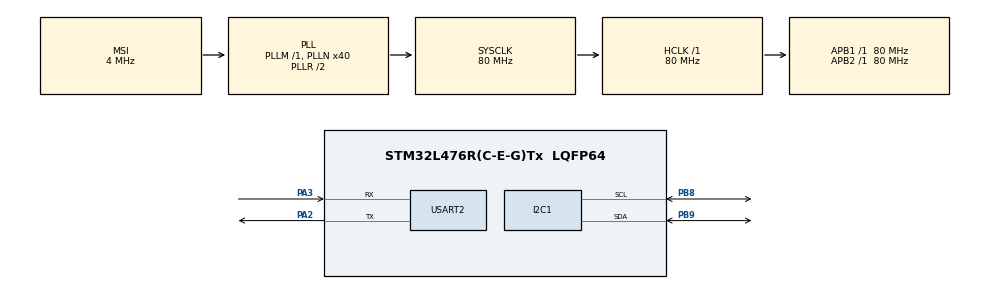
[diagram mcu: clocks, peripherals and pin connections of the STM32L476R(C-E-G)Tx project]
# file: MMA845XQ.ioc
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I2C1.I2C_Fall_Time=20
I2C1.I2C_Rise_Time=20
I2C1.Timing=0x4040415A
Mcu.Family=STM32L4
Mcu.Name=STM32L476R(C-E-G)Tx
Mcu.Package=LQFP64
NVIC.PriorityGroup=NVIC_PRIORITYGROUP_4
PA13\ (JTMS-SWDIO).Mode=Trace_Asynchronous_SW
PA13\ (JTMS-SWDIO).Signal=SYS_JTMS-SWDIO
PA14\ (JTCK-SWCLK).Mode=Trace_Asynchronous_SW
PA14\ (JTCK-SWCLK).Signal=SYS_JTCK-SWCLK
PA2.Mode=Asynchronous
PA2.Signal=USART2_TX
PA3.Mode=Asynchronous
PA3.Signal=USART2_RX
PB3\ (JTDO-TRACESWO).Mode=Trace_Asynchronous_SW
PB3\ (JTDO-TRACESWO).Signal=SYS_JTDO-SWO
PB8.Mode=I2C
PB8.Signal=I2C1_SCL
PB9.Mode=I2C
PB9.Signal=I2C1_SDA
PC14-OSC32_IN\ (PC14).Mode=LSE-External-Oscillator
PC14-OSC32_IN\ (PC14).Signal=RCC_OSC32_IN
PC15-OSC32_OUT\ (PC15).Mode=LSE-External-Oscillator
PC15-OSC32_OUT\ (PC15).Signal=RCC_OSC32_OUT
ProjectManager.HeapSize=0x200
ProjectManager.StackSize=0x400
ProjectManager.TargetToolchain=SW4STM32
RCC.AHBFreq_Value=80000000
RCC.APB1Freq_Value=80000000
RCC.APB1TimFreq_Value=80000000
RCC.APB2Freq_Value=80000000
RCC.APB2TimFreq_Value=80000000
RCC.CortexFreq_Value=80000000
RCC.HCLKFreq_Value=80000000
RCC.HSE_VALUE=8000000
RCC.HSI_VALUE=16000000
RCC.MSI_VALUE=4000000
RCC.PLLN=40
RCC.SYSCLKFreq_VALUE=80000000
RCC.SYSCLKSource=RCC_SYSCLKSOURCE_PLLCLK
RCC.VCOOutputFreq_Value=160000000
USART2.VirtualMode-Asynchronous=VM_ASYNC
VP_WWDG_VS_WWDG.Mode=WWDG_Activate
board=MMA845XQ

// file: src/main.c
/**
 ******************************************************************************
 * File Name          : main.c
 * Description        : Main program body
 ******************************************************************************
 ** This notice applies to any and all portions of this file
 * that are not between comment pairs USER CODE BEGIN and
 * USER CODE END. Other portions of this file, whether
 * inserted by the user or by software development tools
 * are owned by their respective copyright owners.
 *
 * COPYRIGHT(c) 2018 STMicroelectronics
 *
 * Redistribution and use in source and binary forms, with or without modification,
 * are permitted provided that the following conditions are met:
 *   1. Redistributions of source code must retain the above copyright notice,
 *      this list of conditions and the following disclaimer.
 *   2. Redistributions in binary form must reproduce the above copyright notice,
 *      this list of conditions and the following disclaimer in the documentation
 *      and/or other materials provided with the distribution.
 *   3. Neither the name of STMicroelectronics nor the names of its contributors
 *      may be used to endorse or promote products derived from this software
 *      without specific prior written permission.
 *
 * THIS SOFTWARE IS PROVIDED BY THE COPYRIGHT HOLDERS AND CONTRIBUTORS "AS IS"
 * AND ANY EXPRESS OR IMPLIED WARRANTIES, INCLUDING, BUT NOT LIMITED TO, THE
 * IMPLIED WARRANTIES OF MERCHANTABILITY AND FITNESS FOR A PARTICULAR PURPOSE ARE
 * DISCLAIMED. IN NO EVENT SHALL THE COPYRIGHT HOLDER OR CONTRIBUTORS BE LIABLE
 * FOR ANY DIRECT, INDIRECT, INCIDENTAL, SPECIAL, EXEMPLARY, OR CONSEQUENTIAL
 * DAMAGES (INCLUDING, BUT NOT LIMITED TO, PROCUREMENT OF SUBSTITUTE GOODS OR
 * SERVICES; LOSS OF USE, DATA, OR PROFITS; OR BUSINESS INTERRUPTION) HOWEVER
 * CAUSED AND ON ANY THEORY OF LIABILITY, WHETHER IN CONTRACT, STRICT LIABILITY,
 * OR TORT (INCLUDING NEGLIGENCE OR OTHERWISE) ARISING IN ANY WAY OUT OF THE USE
 * OF THIS SOFTWARE, EVEN IF ADVISED OF THE POSSIBILITY OF SUCH DAMAGE.
 *
 ******************************************************************************
 */

#include "main.h"
#include "stm32l4xx_hal.h"
#include "i2c.h"
#include "usart.h"
#include "wwdg.h"
#include "gpio.h"
#include "drv_mma845x.h"

/* USER CODE BEGIN PV */
/* Private variables ---------------------------------------------------------*/
MMA845x_HandleTypeDef hMMA8452Q;
/* USER CODE END PV */

void SystemClock_Config(void);
void BSP_MMA845x_Init(void);
void PrintXYZ(short data);

#ifdef __GNUC__
/* With GCC/RAISONANCE, small printf (option LD Linker->Libraries->Small printf
 set to 'Yes') calls __io_putchar() */
#define PUTCHAR_PROTOTYPE int __io_putchar(int ch)
#else
#define PUTCHAR_PROTOTYPE int fputc(int ch, FILE *f)
#endif /* __GNUC__ */

PUTCHAR_PROTOTYPE {
	/* Place your implementation of fputc here */
	/* e.g. write a character to the USART1 and Loop until the end of transmission */
	HAL_UART_Transmit(&huart2, (uint8_t *) &ch, 1, 0xFFFF);

	return ch;
}
/* USER CODE BEGIN PFP */
/* Private function prototypes -----------------------------------------------*/

/* USER CODE END PFP */

int main(void) {

	/* MCU Configuration----------------------------------------------------------*/

	/* Reset of all peripherals, Initializes the Flash interface and the Systick. */
	HAL_Init();

	/* Configure the system clock */
	SystemClock_Config();

	/* Initialize all configured peripherals */
	MX_GPIO_Init();
	//MX_WWDG_Init();
	MX_USART2_UART_Init();
	MX_I2C1_Init();

	/* USER CODE BEGIN 2 */
	BSP_MMA845x_Init();
	/* USER CODE END 2 */
	printf("Ready\r\n");
	/* Infinite loop */
	while (1) {
		Drv_MMA845x_MainFunction(&hMMA8452Q);
		HAL_Delay(10);
	}

}
void Drv_MMA845x_RxXYZCpltCallback(MMA845x_HandleTypeDef *handle) {

	printf("Counts -> X: %d Y: %d Z: %d \r\n", handle->Data.x, handle->Data.y, handle->Data.z);
	printf("Gs     -> X: %.4f [mg] Y: %.4f [mg] Z: %.4f [mg]\r\n", handle->Data.gx, handle->Data.gy, handle->Data.gz);

}

void BSP_MMA845x_Init(void) {

	hMMA8452Q.Instance = MMA845X_INSTANCE2;
	hMMA8452Q.Init.DataRate = HAL_MMA845x_DATA_RATE_800Hz;
	hMMA8452Q.Init.ActiveSamplingMode = HAL_MMA845x_OVSM_HIGH_RESOLUTION;
	hMMA8452Q.Init.SleepSamplingMode = HAL_MMA845x_OVSM_HIGH_RESOLUTION;
	hMMA8452Q.Init.DynamicRange = HAL_MMA845x_FULL_SCALE_2G;
	hMMA8452Q.Init.SleepRate = HAL_MMA845x_ASLP_RATE_50Hz;

	if (Drv_MMA845x_Init(&hMMA8452Q) != E_OK) {
		_Error_Handler(__FILE__, __LINE__);
	}

}

/** System Clock Configuration
 */
void SystemClock_Config(void) {

	RCC_OscInitTypeDef RCC_OscInitStruct;
	RCC_ClkInitTypeDef RCC_ClkInitStruct;
	RCC_PeriphCLKInitTypeDef PeriphClkInit;

	/**Configure LSE Drive Capability
	 */
	__HAL_RCC_LSEDRIVE_CONFIG(RCC_LSEDRIVE_LOW);

	/**Initializes the CPU, AHB and APB busses clocks
	 */
	RCC_OscInitStruct.OscillatorType = RCC_OSCILLATORTYPE_LSE
			| RCC_OSCILLATORTYPE_MSI;
	RCC_OscInitStruct.LSEState = RCC_LSE_ON;
	RCC_OscInitStruct.MSIState = RCC_MSI_ON;
	RCC_OscInitStruct.MSICalibrationValue = 0;
	RCC_OscInitStruct.MSIClockRange = RCC_MSIRANGE_6;
	RCC_OscInitStruct.PLL.PLLState = RCC_PLL_ON;
	RCC_OscInitStruct.PLL.PLLSource = RCC_PLLSOURCE_MSI;
	RCC_OscInitStruct.PLL.PLLM = 1;
	RCC_OscInitStruct.PLL.PLLN = 40;
	RCC_OscInitStruct.PLL.PLLP = RCC_PLLP_DIV7;
	RCC_OscInitStruct.PLL.PLLQ = RCC_PLLQ_DIV2;
	RCC_OscInitStruct.PLL.PLLR = RCC_PLLR_DIV2;
	if (HAL_RCC_OscConfig(&RCC_OscInitStruct) != HAL_OK) {
		_Error_Handler(__FILE__, __LINE__);
	}

	/**Initializes the CPU, AHB and APB busses clocks
	 */
	RCC_ClkInitStruct.ClockType = RCC_CLOCKTYPE_HCLK | RCC_CLOCKTYPE_SYSCLK
			| RCC_CLOCKTYPE_PCLK1 | RCC_CLOCKTYPE_PCLK2;
	RCC_ClkInitStruct.SYSCLKSource = RCC_SYSCLKSOURCE_PLLCLK;
	RCC_ClkInitStruct.AHBCLKDivider = RCC_SYSCLK_DIV1;
	RCC_ClkInitStruct.APB1CLKDivider = RCC_HCLK_DIV1;
	RCC_ClkInitStruct.APB2CLKDivider = RCC_HCLK_DIV1;

	if (HAL_RCC_ClockConfig(&RCC_ClkInitStruct, FLASH_LATENCY_3) != HAL_OK) {
		_Error_Handler(__FILE__, __LINE__);
	}

	PeriphClkInit.PeriphClockSelection = RCC_PERIPHCLK_USART2
			| RCC_PERIPHCLK_I2C1;
	PeriphClkInit.Usart2ClockSelection = RCC_USART2CLKSOURCE_PCLK1;
	PeriphClkInit.I2c1ClockSelection = RCC_I2C1CLKSOURCE_PCLK1;
	if (HAL_RCCEx_PeriphCLKConfig(&PeriphClkInit) != HAL_OK) {
		_Error_Handler(__FILE__, __LINE__);
	}

	/**Configure the main internal regulator output voltage
	 */
	if (HAL_PWREx_ControlVoltageScaling(PWR_REGULATOR_VOLTAGE_SCALE1)
			!= HAL_OK) {
		_Error_Handler(__FILE__, __LINE__);
	}

	/**Configure the Systick interrupt time
	 */
	HAL_SYSTICK_Config(HAL_RCC_GetHCLKFreq() / 1000);

	/**Configure the Systick
	 */
	HAL_SYSTICK_CLKSourceConfig(SYSTICK_CLKSOURCE_HCLK);

	/**Enable MSI Auto calibration
	 */
	HAL_RCCEx_EnableMSIPLLMode();

	/* SysTick_IRQn interrupt configuration */
	HAL_NVIC_SetPriority(SysTick_IRQn, 0, 0);
}

void _Error_Handler(char * file, int line) {
	while (1) {
	}
}

/************************ (C) COPYRIGHT STMicroelectronics *****END OF FILE****/
